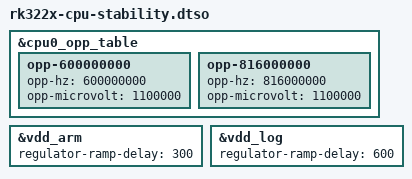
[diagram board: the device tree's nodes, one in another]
/dts-v1/;
/plugin/;

/ {

	/*
		Device tree overlay that tries to overcome issues on power regulators (expecially ARM
		power regulator) increasing lowest voltage and adding settling time to allow voltage
		stabilization
	*/

	fragment@0 {
		target = <&cpu0_opp_table>;
		__overlay__ {

			/*
				Increase 600 and 800 Mhz operating points voltage to decrease the range
				between minimum and maximum voltages
			*/
			opp-600000000 {
				opp-hz = /bits/ 64 <600000000>;
				opp-microvolt = <1100000>;
			};

			opp-816000000 {
				opp-hz = /bits/ 64 <816000000>;
				opp-microvolt = <1100000>;
			};

		};
	};

	fragment@1 {
		target = <&vdd_arm>;
		__overlay__ {

			regulator-ramp-delay = <300>; // 30 uV/us, so 0.3v transition settling time is 1ms

		};
	};

	fragment@2 {
		target = <&vdd_log>;
		__overlay__ {

			regulator-ramp-delay = <600>; // 600 uV/us, so 0,3v transition settling time is 0.5ms

		};

	};

};
